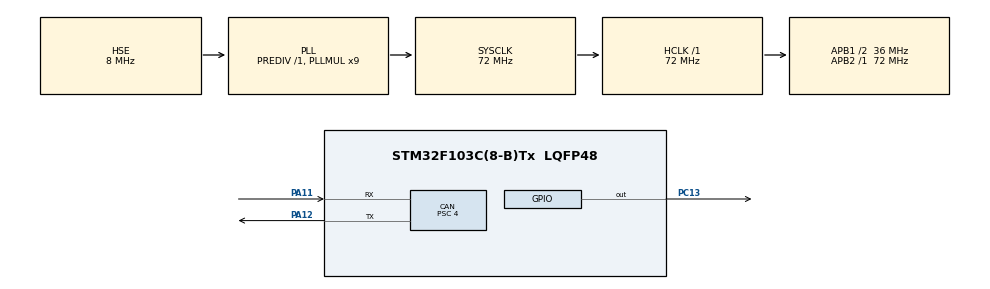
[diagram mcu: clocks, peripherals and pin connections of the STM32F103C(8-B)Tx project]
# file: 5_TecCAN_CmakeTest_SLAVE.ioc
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CAN.ABOM=ENABLE
CAN.BS1=CAN_BS1_13TQ
CAN.BS2=CAN_BS2_4TQ
CAN.CalculateBaudRate=500000
CAN.CalculateTimeBit=2000
CAN.CalculateTimeQuantum=111.11111111111111
CAN.Mode=CAN_MODE_NORMAL
CAN.NART=ENABLE
CAN.Prescaler=4
CAN.SJW=CAN_SJW_1TQ
CAN.TXFP=ENABLE
Mcu.Family=STM32F1
Mcu.Name=STM32F103C(8-B)Tx
Mcu.Package=LQFP48
NVIC.PriorityGroup=NVIC_PRIORITYGROUP_4
NVIC.USB_LP_CAN1_RX0_IRQn=true\:0\:0\:false\:false\:true\:true\:true\:true
PA11.Mode=CAN_Activate
PA11.Signal=CAN_RX
PA12.Mode=CAN_Activate
PA12.Signal=CAN_TX
PA13.Mode=Serial_Wire
PA13.Signal=SYS_JTMS-SWDIO
PA14.Mode=Serial_Wire
PA14.Signal=SYS_JTCK-SWCLK
PC13-TAMPER-RTC.PinState=GPIO_PIN_SET
PC13-TAMPER-RTC.Signal=GPIO_Output
PD0-OSC_IN.Mode=HSE-External-Oscillator
PD0-OSC_IN.Signal=RCC_OSC_IN
PD1-OSC_OUT.Mode=HSE-External-Oscillator
PD1-OSC_OUT.Signal=RCC_OSC_OUT
ProjectManager.HeapSize=0x200
ProjectManager.StackSize=0x800
ProjectManager.TargetToolchain=CMake
RCC.AHBFreq_Value=72000000
RCC.APB1CLKDivider=RCC_HCLK_DIV2
RCC.APB1Freq_Value=36000000
RCC.APB1TimFreq_Value=72000000
RCC.APB2Freq_Value=72000000
RCC.APB2TimFreq_Value=72000000
RCC.HCLKFreq_Value=72000000
RCC.PLLMUL=RCC_PLL_MUL9
RCC.PLLSourceVirtual=RCC_PLLSOURCE_HSE
RCC.SYSCLKFreq_VALUE=72000000
RCC.SYSCLKSource=RCC_SYSCLKSOURCE_PLLCLK
RCC.USBFreq_Value=72000000
board=custom

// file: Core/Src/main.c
/* USER CODE BEGIN Header */
/**
  ******************************************************************************
  * @file           : main.c
  * @brief          : Main program body
  ******************************************************************************
  * @attention
  *
  * Copyright (c) 2025 STMicroelectronics.
  * All rights reserved.
  *
  * This software is licensed under terms that can be found in the LICENSE file
  * in the root directory of this software component.
  * If no LICENSE file comes with this software, it is provided AS-IS.
  *
  ******************************************************************************
  */
/* USER CODE END Header */
#include "main.h"
#include "can.h"
#include "gpio.h"
#include "stm32f1xx_hal_gpio.h"

/* USER CODE BEGIN PV */
CAN_TxHeaderTypeDef TxHeader;
CAN_RxHeaderTypeDef RxHeader;
uint8_t TxData[8] = {0x01, 0x02, 0x03, 0x04, 0x05, 0x06, 0x07, 0x08};
uint8_t RxData[8];
uint32_t TxMailbox;
/* USER CODE END PV */

void SystemClock_Config(void);

int main(void)
{

  /* MCU Configuration--------------------------------------------------------*/

  /* Reset of all peripherals, Initializes the Flash interface and the Systick. */
  HAL_Init();

  /* Configure the system clock */
  SystemClock_Config();

  /* Initialize all configured peripherals */
  MX_GPIO_Init();
  MX_CAN_Init();
  /* USER CODE BEGIN 2 */

  CAN_FilterTypeDef sFilterConfig;

  // 配置过滤器：接收所有消息
  sFilterConfig.FilterBank = 0;
  sFilterConfig.FilterMode = CAN_FILTERMODE_IDMASK;
  sFilterConfig.FilterScale = CAN_FILTERSCALE_32BIT;
  sFilterConfig.FilterIdHigh = 0x0000;
  sFilterConfig.FilterIdLow = 0x0000;
  sFilterConfig.FilterMaskIdHigh = 0x0000;
  sFilterConfig.FilterMaskIdLow = 0x0000;
  sFilterConfig.FilterFIFOAssignment = CAN_RX_FIFO0;
  sFilterConfig.FilterActivation = ENABLE;
  sFilterConfig.SlaveStartFilterBank = 0; // F103单CAN必须设为0

  if (HAL_CAN_ConfigFilter(&hcan, &sFilterConfig) != HAL_OK) {
      Error_Handler();
  }

  // 启动 CAN
  if (HAL_CAN_Start(&hcan) != HAL_OK) {
      Error_Handler();
  }

  // 使能接收中断
  if (HAL_CAN_ActivateNotification(&hcan, CAN_IT_RX_FIFO0_MSG_PENDING) != HAL_OK) {
      Error_Handler();
  }

  // 初始化发送报文头
  TxHeader.StdId = 0x456;
  TxHeader.RTR = CAN_RTR_DATA;
  TxHeader.IDE = CAN_ID_STD;
  TxHeader.DLC = 8;
  TxHeader.TransmitGlobalTime = DISABLE;

  /* USER CODE END 2 */

  /* Infinite loop */
  /* USER CODE BEGIN WHILE */
  while (1)
  {
    // 发送测试消息
     if (HAL_CAN_GetTxMailboxesFreeLevel(&hcan) > 0)
    {
         HAL_CAN_AddTxMessage(&hcan, &TxHeader, TxData, &TxMailbox);
    }
     HAL_Delay(100);
    // HAL_GPIO_TogglePin(GPIOC, GPIO_PIN_13);

    /* USER CODE END WHILE */

  }
}

void SystemClock_Config(void)
{
  RCC_OscInitTypeDef RCC_OscInitStruct = {0};
  RCC_ClkInitTypeDef RCC_ClkInitStruct = {0};

  /** Initializes the RCC Oscillators according to the specified parameters
  * in the RCC_OscInitTypeDef structure.
  */
  RCC_OscInitStruct.OscillatorType = RCC_OSCILLATORTYPE_HSE;
  RCC_OscInitStruct.HSEState = RCC_HSE_ON;
  RCC_OscInitStruct.HSEPredivValue = RCC_HSE_PREDIV_DIV1;
  RCC_OscInitStruct.HSIState = RCC_HSI_ON;
  RCC_OscInitStruct.PLL.PLLState = RCC_PLL_ON;
  RCC_OscInitStruct.PLL.PLLSource = RCC_PLLSOURCE_HSE;
  RCC_OscInitStruct.PLL.PLLMUL = RCC_PLL_MUL9;
  if (HAL_RCC_OscConfig(&RCC_OscInitStruct) != HAL_OK)
  {
    Error_Handler();
  }

  /** Initializes the CPU, AHB and APB buses clocks
  */
  RCC_ClkInitStruct.ClockType = RCC_CLOCKTYPE_HCLK|RCC_CLOCKTYPE_SYSCLK
                              |RCC_CLOCKTYPE_PCLK1|RCC_CLOCKTYPE_PCLK2;
  RCC_ClkInitStruct.SYSCLKSource = RCC_SYSCLKSOURCE_PLLCLK;
  RCC_ClkInitStruct.AHBCLKDivider = RCC_SYSCLK_DIV1;
  RCC_ClkInitStruct.APB1CLKDivider = RCC_HCLK_DIV2;
  RCC_ClkInitStruct.APB2CLKDivider = RCC_HCLK_DIV1;

  if (HAL_RCC_ClockConfig(&RCC_ClkInitStruct, FLASH_LATENCY_2) != HAL_OK)
  {
    Error_Handler();
  }
}

/* USER CODE BEGIN 4 */

// 弃用

// void CAN_UserRxCallback(uint32_t id, uint8_t *data, uint8_t len)
// {
//     if (id == 0x123)
//     {
//         HAL_GPIO_TogglePin(GPIOC, GPIO_PIN_13);
//     }
// }

/**
 * @brief  CAN 接收 FIFO0 消息挂起回调函数（中断上下文）
 * @note   当 FIFO0 收到一帧有效报文时，HAL 自动调用此函数
 * @param  hcan：指向 CAN 句柄，携带接收 FIFO0 的报文
 * @retval 无
 */
void HAL_CAN_RxFifo0MsgPendingCallback(CAN_HandleTypeDef *hcan)
{
    /* 1. 从 FIFO0 读取报文，填充 RxHeader 与 RxData */
    if (HAL_CAN_GetRxMessage(hcan, CAN_RX_FIFO0, &RxHeader, RxData) == HAL_OK)
    {
         /* 2. 仅处理来自 Model-A（标准 ID = 0x123）的心跳或指令帧 */

        // 如果收到了 ID 为 0x123 的消息（就是model-A发的）
        if (RxHeader.StdId == 0x123)
        {
            /* 3. 翻转板载 LED（GPIOC13）以指示收到 Model-A 数据 */
            HAL_GPIO_TogglePin(GPIOC, GPIO_PIN_13);
        }
    }
}

/* USER CODE END 4 */

void Error_Handler(void)
{
  __disable_irq();
  while (1)
  {
  }
}
